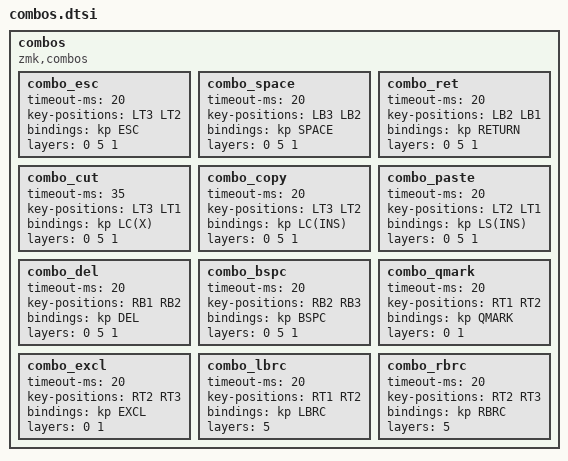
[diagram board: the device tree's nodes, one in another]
#include <dt-bindings/zmk/keys.h>

combos {
        compatible = "zmk,combos";
        combo_esc {
            timeout-ms = <20>;
            key-positions = <LT3 LT2>;
            bindings = <&kp ESC>;
            layers = <0 5 1>;  /* DEF NAV NUM */
        };
        combo_space {
            timeout-ms = <20>;
            key-positions = <LB3 LB2>;
            bindings = <&kp SPACE>;
            layers = <0 5 1>;
        };
        combo_ret {
            timeout-ms = <20>;
            key-positions = <LB2 LB1>;
            bindings = <&kp RETURN>;
            layers = <0 5 1>;
        };
        
       
        combo_cut {
            timeout-ms = <35>;
            key-positions = <LT3 LT1>;
            bindings = <&kp LC(X)>;
            layers = <0 5 1>;
        };
        combo_copy {
            timeout-ms = <20>;
            key-positions = <LT3 LT2>;
            bindings = <&kp LC(INS)>;
            layers = <0 5 1>;
        };
        combo_paste {
            timeout-ms = <20>;
            key-positions = <LT2 LT1>;
            bindings = <&kp LS(INS)>;
            layers = <0 5 1>;
        };
        combo_del {
            timeout-ms = <20>;
            key-positions = <RB1 RB2>;
            bindings = <&kp DEL>;
            layers = <0 5 1>;
        };
        combo_bspc {
            timeout-ms = <20>;
            key-positions = <RB2 RB3>;
            bindings = <&kp BSPC>;
            layers = <0 5 1>;
        };
        combo_qmark {
            timeout-ms = <20>;
            key-positions = <RT1 RT2>;
            bindings = <&kp QMARK>;
            layers = <0 1>;
        };
        combo_excl {
            timeout-ms = <20>;
            key-positions = <RT2 RT3>;
            bindings = <&kp EXCL>;
            layers = <0 1>;
        };
        combo_lbrc {
            timeout-ms = <20>;
            key-positions = <RT1 RT2>;
            bindings = <&kp LBRC>;
            layers = <5>;
        };
        combo_rbrc {
            timeout-ms = <20>;
            key-positions = <RT2 RT3>;
            bindings = <&kp RBRC>;
            layers = <5>;
        };
};
